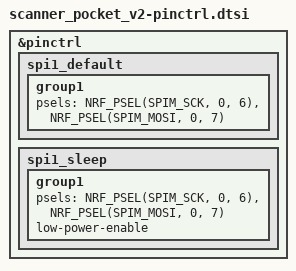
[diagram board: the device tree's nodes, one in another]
/*
 * Scanner Pocket v2 pin control.
 *
 * LCD nets per HANDOVER 14.2 (SCLK P0.06, SI P0.07). The LS013B7DH05 is
 * write-only, so there is no MISO. Re-check against the finished KiCad
 * netlist before enabling the SPI node.
 *
 * SPDX-License-Identifier: MIT
 */

&pinctrl {
    spi1_default: spi1_default {
        group1 {
            psels = <NRF_PSEL(SPIM_SCK, 0, 6)>,
                    <NRF_PSEL(SPIM_MOSI, 0, 7)>;
        };
    };

    spi1_sleep: spi1_sleep {
        group1 {
            psels = <NRF_PSEL(SPIM_SCK, 0, 6)>,
                    <NRF_PSEL(SPIM_MOSI, 0, 7)>;
            low-power-enable;
        };
    };
};
